# ESP32S31_RADIO register map
Vendor: Espressif; Series: ESP32-S31; File version: 3.52
Registers are 32-bit, read-write, no defined reset value unless marked. A register's access mark holds for its fields unless they carry their own. Offsets are from the block's base; [hi:lo] are bit positions; {n}, {i} and the like mark numbered series.

## WIFI_MAC_CRYPTO_CONTROL — Per-interface hardware-crypto controls, shared policy mask and key validity bitmap recovered from complete libpp hal_crypto leaves.
Base 0x20104800
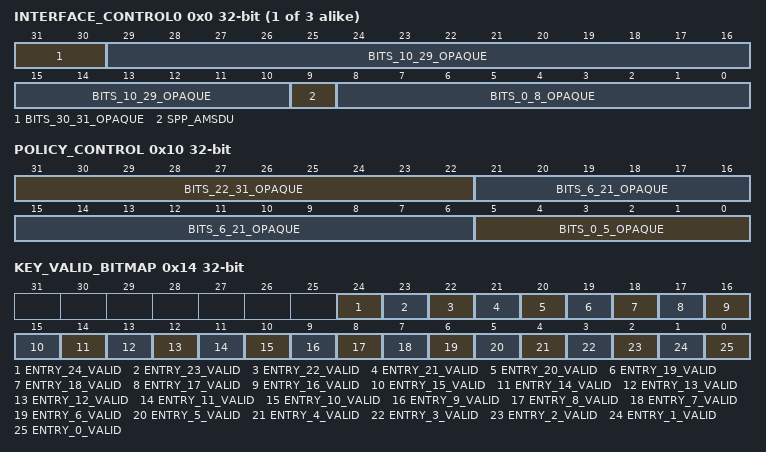
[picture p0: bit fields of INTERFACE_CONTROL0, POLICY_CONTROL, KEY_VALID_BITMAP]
{0x0+4i} INTERFACE_CONTROL{i} (i=0..2) — Project-assigned name. STA, AP and NAN interface controls selected by hal_crypto_enable. Ordinary CCMP writes 0x00030103 and additionally enables SPP A-MSDU when the association negotiated it. SPP is shared by every key on this interface.
  [31:30] BITS_30_31_OPAQUE — Opaque: meaning not established. Complete ordinary enable clears both high bits; one algorithm branch sets bit 31.
  [29:10] BITS_10_29_OPAQUE — Opaque: meaning not established. Upper algorithm and management-frame policy fields composed by hal_crypto_enable.
  [9] SPP_AMSDU — Project-assigned name. Authenticate the QoS A-MSDU-present bit in CCMP for this interface. SOURCE(esp32s31): libpp[hal_crypto.o]::hal_crypto_enable +0x2e..+0x34 consumes argument four from libpp[wdev.o]::wDev_Insert_KeyEntry; libnet80211[ieee80211_supplicant.o]::ieee80211_get_spp selects the association decision upstream.
  [8:0] BITS_0_8_OPAQUE — Opaque: meaning not established. Low algorithm and enable fields composed by hal_crypto_enable.
0x0C WORD_000C_OPAQUE — Opaque: meaning not established. Fourth full-word cold-init store, cleared by complete hal_crypto_init. Its algorithm-specific meaning is not yet recovered.
  [31:0] BITS_0_31_OPAQUE — Opaque: meaning not established.
0x10 POLICY_CONTROL — Project-assigned name. Shared policy word. The ordinary non-algorithm-four enable path preserves bits 31:22 and 5:0 while clearing bits 21:6.
  [31:22] BITS_22_31_OPAQUE — Opaque: meaning not established.
  [21:6] BITS_6_21_OPAQUE — Opaque: meaning not established. Cleared by the reachable STA CCMP enable transaction.
  [5:0] BITS_0_5_OPAQUE — Opaque: meaning not established.
0x14 KEY_VALID_BITMAP — Project-assigned name. One validity bit per one of the 25 evidenced hardware key entries.
  [24] ENTRY_24_VALID — Project-assigned name. Validity of key-table entry twenty-four.
  [23] ENTRY_23_VALID — Project-assigned name. Validity of key-table entry twenty-three.
  [22] ENTRY_22_VALID — Project-assigned name. Validity of key-table entry twenty-two.
  [21] ENTRY_21_VALID — Project-assigned name. Validity of key-table entry twenty-one.
  [20] ENTRY_20_VALID — Project-assigned name. Validity of key-table entry twenty.
  [19] ENTRY_19_VALID — Project-assigned name. Validity of key-table entry nineteen.
  [18] ENTRY_18_VALID — Project-assigned name. Validity of key-table entry eighteen.
  [17] ENTRY_17_VALID — Project-assigned name. Validity of key-table entry seventeen.
  [16] ENTRY_16_VALID — Project-assigned name. Validity of key-table entry sixteen.
  [15] ENTRY_15_VALID — Project-assigned name. Validity of key-table entry fifteen.
  [14] ENTRY_14_VALID — Project-assigned name. Validity of key-table entry fourteen.
  [13] ENTRY_13_VALID — Project-assigned name. Validity of key-table entry thirteen.
  [12] ENTRY_12_VALID — Project-assigned name. Validity of key-table entry twelve.
  [11] ENTRY_11_VALID — Project-assigned name. Validity of key-table entry eleven.
  [10] ENTRY_10_VALID — Project-assigned name. Validity of key-table entry ten.
  [9] ENTRY_9_VALID — Project-assigned name. Validity of key-table entry nine.
  [8] ENTRY_8_VALID — Project-assigned name. Validity of key-table entry eight.
  [7] ENTRY_7_VALID — Project-assigned name. Validity of key-table entry seven.
  [6] ENTRY_6_VALID — Project-assigned name. Validity of key-table entry six.
  [5] ENTRY_5_VALID — Project-assigned name. Validity of key-table entry five.
  [4] ENTRY_4_VALID — Project-assigned name. Validity of key-table entry four.
  [3] ENTRY_3_VALID — Project-assigned name. Validity of key-table entry three.
  [2] ENTRY_2_VALID — Project-assigned name. Validity of key-table entry two.
  [1] ENTRY_1_VALID — Project-assigned name. Validity of key-table entry one.
  [0] ENTRY_0_VALID — Project-assigned name. Validity of key-table entry zero.
